AUTOSAR XML (schema 4-0-3)
package /PATAC/MSM/ComponentTypes
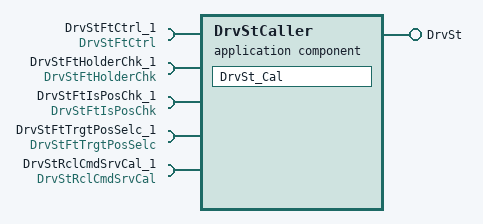
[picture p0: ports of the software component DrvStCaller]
  application sw component type DrvStCaller
    provide port DrvSt: server-com-spec{operation=DrvSt/Cal, queue-length=1}, provided-interface=DrvSt
    5 x require port:
      DrvStFtCtrl_1: client-com-spec=DrvStFtCtrl/Cal, required-interface=DrvStFtCtrl
      DrvStFtHolderChk_1: client-com-spec=DrvStFtHolderChk/Cal, required-interface=DrvStFtHolderChk
      DrvStFtIsPosChk_1: client-com-spec=DrvStFtIsPosChk/Cal, required-interface=DrvStFtIsPosChk
      DrvStFtTrgtPosSelc_1: client-com-spec=DrvStFtTrgtPosSelc/Cal, required-interface=DrvStFtTrgtPosSelc
      DrvStRclCmdSrvCal_1: client-com-spec=DrvStRclCmdSrvCal/Cal, required-interface=DrvStRclCmdSrvCal
    behavior DrvStCaller_InternalBehavior
      operation invoked event OIT_DrvSt_Cal_DrvSt_Cal: start-on-event=DrvSt_Cal, operation=DrvSt.Cal
      runnable DrvSt_Cal
        5 x sync call, all with timeout=0:
          SC_DrvStFtCtrl_1_Cal: operation=DrvStFtCtrl_1.Cal
          SC_DrvStFtHolderChk_1_Cal: operation=DrvStFtHolderChk_1.Cal
          SC_DrvStFtIsPosChk_1_Cal: operation=DrvStFtIsPosChk_1.Cal
          SC_DrvStFtTrgtPosSelc_1_Cal: operation=DrvStFtTrgtPosSelc_1.Cal
          SC_DrvStRclCmdSrvCal_1_Cal: operation=DrvStRclCmdSrvCal_1.Cal
  swc implementation DrvStCaller_Implementation: behavior=DrvStCaller_InternalBehavior
    code-descriptors:
      code Default: artifact-descriptors=autosar-engineering-object={short-label=Default, category=SWSRC}
package /PATAC/MSM/ModeAdjust/PortInterface
  6 x client server interface:
    DrvSt
      operation Cal
    DrvStFtCtrl
      operation Cal
    DrvStFtHolderChk
      operation Cal
    DrvStFtIsPosChk
      operation Cal
    DrvStFtTrgtPosSelc
      operation Cal
    DrvStRclCmdSrvCal
      operation Cal
